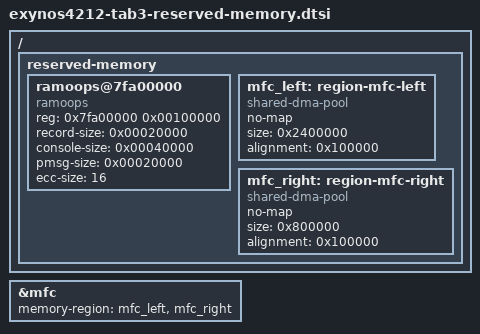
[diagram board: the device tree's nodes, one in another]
// SPDX-License-Identifier: GPL-2.0
/*
 * Reserved memory layout used by Samsung Galaxy Tab 3 (SM-T31x).
 *
 * Keep ramoops at the stock/delivered address and retain the Exynos MFC
 * carve-outs used by the common Exynos4 video codec driver.
 */

/ {
	reserved-memory {
		#address-cells = <1>;
		#size-cells = <1>;
		ranges;

		ramoops@7fa00000 {
			compatible = "ramoops";
			reg = <0x7fa00000 0x00100000>;
			record-size = <0x00020000>;
			console-size = <0x00040000>;
			pmsg-size = <0x00020000>;
			ecc-size = <16>;
			status = "okay";
		};

		mfc_left: region-mfc-left {
			compatible = "shared-dma-pool";
			no-map;
			size = <0x2400000>;
			alignment = <0x100000>;
		};

		mfc_right: region-mfc-right {
			compatible = "shared-dma-pool";
			no-map;
			size = <0x800000>;
			alignment = <0x100000>;
		};
	};
};

&mfc {
	memory-region = <&mfc_left>, <&mfc_right>;
};
